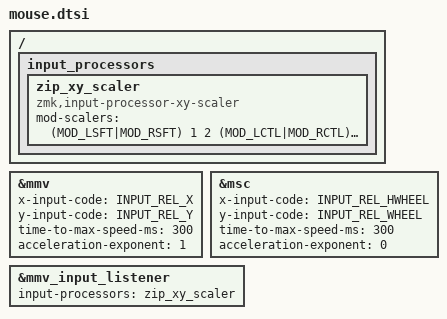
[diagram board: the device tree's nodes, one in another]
#include <dt-bindings/zmk/pointing.h>
#include <behaviors/mouse_keys.dtsi>

#define ZMK_POINTING_DEFAULT_MOVE_VAL 4000  // default: 600
#define ZMK_POINTING_DEFAULT_SCRL_VAL 200    // default: 10

#undef MOVE_UP
#undef MOVE_DOWN
#undef MOVE_LEFT
#undef MOVE_RIGHT
#define MOVE_UP MOVE_Y(-U_MOUSE_MOVE_MAX)
#define MOVE_DOWN MOVE_Y(U_MOUSE_MOVE_MAX)
#define MOVE_LEFT MOVE_X(-U_MOUSE_MOVE_MAX)
#define MOVE_RIGHT MOVE_X(U_MOUSE_MOVE_MAX)

#undef SCROLL_UP
#undef SCROLL_DOWN
#undef SCROLL_LEFT
#undef SCROLL_RIGHT
#define SCROLL_UP SCRL_Y(U_MOUSE_SCROLL_MAX)
#define SCROLL_DOWN SCRL_Y(-U_MOUSE_SCROLL_MAX)
#define SCROLL_LEFT SCRL_X(-U_MOUSE_SCROLL_MAX)
#define SCROLL_RIGHT SCRL_X(U_MOUSE_SCROLL_MAX)

#define U_BTN1 &mkp MB1
#define U_BTN2 &mkp MB2
#define U_BTN3 &mkp MB3
#define U_MS_U &mmv MOVE_UP
#define U_MS_D &mmv MOVE_DOWN
#define U_MS_L &mmv MOVE_LEFT
#define U_MS_R &mmv MOVE_RIGHT
#define U_WH_U &msc SCROLL_UP
#define U_WH_D &msc SCROLL_DOWN
#define U_WH_L &msc SCROLL_LEFT
#define U_WH_R &msc SCROLL_RIGHT

&mmv {
    x-input-code = <INPUT_REL_X>;
    y-input-code = <INPUT_REL_Y>;
    time-to-max-speed-ms = <300>;
    acceleration-exponent = <1>;
};

&msc {
    x-input-code = <INPUT_REL_HWHEEL>;
    y-input-code = <INPUT_REL_WHEEL>;
    time-to-max-speed-ms = <300>;
    acceleration-exponent = <0>;
};

&mmv_input_listener {
    input-processors = <&zip_xy_scaler>;
};

/ {
    input_processors {
        zip_xy_scaler: zip_xy_scaler {
            compatible = "zmk,input-processor-xy-scaler";
            mod-scalers = <
                (MOD_LSFT|MOD_RSFT) 1 2   // Shift = half speed
                (MOD_LCTL|MOD_RCTL) 2 1   // Ctrl = double speed
            >;
        };
    };
};
